AUTOSAR XML (schema 00049)
package /Application/DltConfig
  dlt log channel to process mapping DltLogChannelToProcessMapping_SOA_SmartFilm_TO_SOA_SmartFilm: dlt-log-channel=SOA_SmartFilm, process=SOA_SmartFilm
package /Application/Executable
  executable SOA_SmartFilm: category=APPLICATION_LEVEL, logging-behavior=USES-LOGGING, reporting-behavior=REPORTS-EXECUTION-STATE, version=1.0.0
    root sw component prototype AA: application-type=SOA_SmartFilm
package /Application/Manifest
  service instance to port prototype mapping SOA_SmartFilm_AA_PPort_SOA_SmartFilm: port-prototype=AA.PPort_SOA_SmartFilm, process=SOA_SmartFilm, service-instance=Provider_SoaSmartFilm
  service instance to port prototype mapping SOA_SmartFilm_AA_RPort_Zone5_SmtFilm: port-prototype=AA.RPort_Zone5_SmtFilm, process=SOA_SmartFilm, service-instance=Consumer_Zone5SmtFilm
package /Application/Process
  process SOA_SmartFilm: executable=SOA_SmartFilm, state-dependent-startup-config{function-group-state=[SC.On, SC.Verify], resource-group=DefaultResourceGroup, startup-config=SOA}
    process state machine SOA_SmartFilm: type=ProcessState
package /Application/SwComponent
  adaptive application sw component type Application35
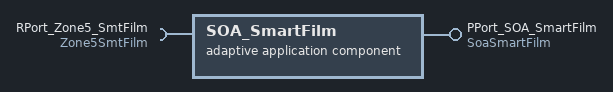
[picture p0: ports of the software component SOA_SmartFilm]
  adaptive application sw component type SOA_SmartFilm
    provide port PPort_SOA_SmartFilm: provided-interface=SoaSmartFilm
    require port RPort_Zone5_SmtFilm: required-interface=Zone5SmtFilm
